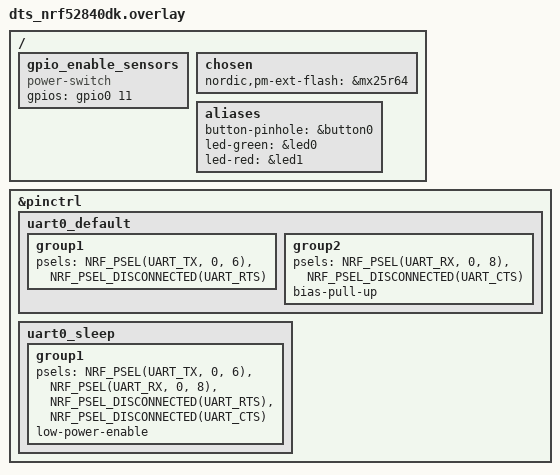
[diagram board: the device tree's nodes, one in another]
/**
 * @copyright Ruuvi Innovations Ltd, license BSD-3-Clause.
 */

/* Disconnect CTS and RTS lines from pins.
* This is a temporary workaround for increased current consumption
* observed on nRF52840 v3.0.0 only (~450 uA more then on v2.1.0).
*/
&pinctrl {
        uart0_default: uart0_default {
                group1 {
                        psels = <NRF_PSEL(UART_TX, 0, 6)>,
                                <NRF_PSEL_DISCONNECTED(UART_RTS)>;
                };
                group2 {
                        psels = <NRF_PSEL(UART_RX, 0, 8)>,
                                <NRF_PSEL_DISCONNECTED(UART_CTS)>;
                        bias-pull-up;
                };
        };

        uart0_sleep: uart0_sleep {
                group1 {
                        psels = <NRF_PSEL(UART_TX, 0, 6)>,
                                <NRF_PSEL(UART_RX, 0, 8)>,
                                <NRF_PSEL_DISCONNECTED(UART_RTS)>,
                                <NRF_PSEL_DISCONNECTED(UART_CTS)>;
                        low-power-enable;
                };
        };
};

/ {
	gpio_enable_sensors: gpio_enable_sensors {
		compatible = "power-switch";
		status = "okay";
		gpios = <&gpio0 11 (GPIO_ACTIVE_HIGH | GPIO_PULL_DOWN)>;
	};
};

/ {
	chosen {
		nordic,pm-ext-flash = &mx25r64;
	};
};

/ {
	aliases {
		button-pinhole = &button0;
		led-green = &led0;
		led-red = &led1;
	};
};

